AUTOSAR XML (schema 00046)
package /ComponentTypes
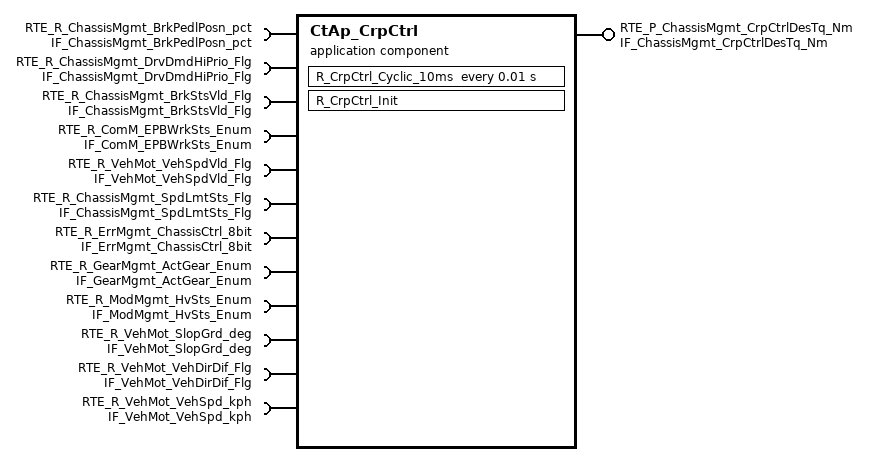
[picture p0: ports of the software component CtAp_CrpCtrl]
  application sw component type CtAp_CrpCtrl
    provide port RTE_P_ChassisMgmt_CrpCtrlDesTq_Nm: nonqueued-sender-com-spec{data-element=tec_ChassisMgmt_CrpCtrlDesTq_Nm, init-value=0}, provided-interface=IF_ChassisMgmt_CrpCtrlDesTq_Nm
    12 x require port:
      RTE_R_ChassisMgmt_BrkPedlPosn_pct: nonqueued-receiver-com-spec{data-element=tec_ChassisMgmt_BrkPedlPosn_pct, filter=data-filter-type=ALWAYS, init-value=0}, required-interface=IF_ChassisMgmt_BrkPedlPosn_pct
      RTE_R_ChassisMgmt_DrvDmdHiPrio_Flg: nonqueued-receiver-com-spec{data-element=tec_ChassisMgmt_DrvDmdHiPrio_Flg, filter=data-filter-type=ALWAYS, init-value=0}, required-interface=IF_ChassisMgmt_DrvDmdHiPrio_Flg
      RTE_R_ChassisMgmt_BrkStsVld_Flg: nonqueued-receiver-com-spec{data-element=tec_ChassisMgmt_BrkStsVld_Flg, filter=data-filter-type=ALWAYS, init-value=0}, required-interface=IF_ChassisMgmt_BrkStsVld_Flg
      RTE_R_ComM_EPBWrkSts_Enum: nonqueued-receiver-com-spec{data-element=tec_ComM_EPBWrkSts_Enum, filter=data-filter-type=ALWAYS, init-value=0}, required-interface=IF_ComM_EPBWrkSts_Enum
      RTE_R_VehMot_VehSpdVld_Flg: nonqueued-receiver-com-spec{data-element=tec_VehMot_VehSpdVld_Flg, filter=data-filter-type=ALWAYS, init-value=0}, required-interface=IF_VehMot_VehSpdVld_Flg
      RTE_R_ChassisMgmt_SpdLmtSts_Flg: nonqueued-receiver-com-spec{data-element=tec_ChassisMgmt_SpdLmtSts_Flg, filter=data-filter-type=ALWAYS, init-value=0}, required-interface=IF_ChassisMgmt_SpdLmtSts_Flg
      RTE_R_ErrMgmt_ChassisCtrl_8bit: nonqueued-receiver-com-spec{data-element=tec_ErrMgmt_ChassisCtrl_8bit, filter=data-filter-type=ALWAYS, init-value=0}, required-interface=IF_ErrMgmt_ChassisCtrl_8bit
      RTE_R_GearMgmt_ActGear_Enum: nonqueued-receiver-com-spec{data-element=tec_GearMgmt_ActGear_Enum, filter=data-filter-type=ALWAYS, init-value=0}, required-interface=IF_GearMgmt_ActGear_Enum
      RTE_R_ModMgmt_HvSts_Enum: nonqueued-receiver-com-spec{data-element=tec_ModMgmt_HvSts_Enum, filter=data-filter-type=ALWAYS, init-value=0}, required-interface=IF_ModMgmt_HvSts_Enum
      RTE_R_VehMot_SlopGrd_deg: nonqueued-receiver-com-spec{data-element=tec_VehMot_SlopGrd_deg, filter=data-filter-type=ALWAYS, init-value=0}, required-interface=IF_VehMot_SlopGrd_deg
      RTE_R_VehMot_VehDirDif_Flg: nonqueued-receiver-com-spec{data-element=tec_VehMot_VehDirDif_Flg, filter=data-filter-type=ALWAYS, init-value=0}, required-interface=IF_VehMot_VehDirDif_Flg
      RTE_R_VehMot_VehSpd_kph: nonqueued-receiver-com-spec{data-element=tec_VehMot_VehSpd_kph, filter=data-filter-type=ALWAYS, init-value=0}, required-interface=IF_VehMot_VehSpd_kph
    behavior CtAp_CrpCtrl_InternalBehavior
      init event CtAp_CrpCtrl_InitEvent: start-on-event=R_CrpCtrl_Init
      timing event TMT_R_CrpCtrl_Cyclic_10ms: start-on-event=R_CrpCtrl_Cyclic_10ms, period=0.01
      runnable R_CrpCtrl_Init
      runnable R_CrpCtrl_Cyclic_10ms
        data-receive-point-by-arguments:
          12 x access:
            REC_RTE_R_ChassisMgmt_BrkPedlPosn_pct_tec_ChassisMgmt_BrkPedlPosn_pct: accessed-variable=RTE_R_ChassisMgmt_BrkPedlPosn_pct.tec_ChassisMgmt_BrkPedlPosn_pct
            REC_RTE_R_ChassisMgmt_BrkStsVld_Flg_tec_ChassisMgmt_BrkStsVld_Flg: accessed-variable=RTE_R_ChassisMgmt_BrkStsVld_Flg.tec_ChassisMgmt_BrkStsVld_Flg
            REC_RTE_R_ChassisMgmt_DrvDmdHiPrio_Flg_tec_ChassisMgmt_DrvDmdHiPrio_Flg: accessed-variable=RTE_R_ChassisMgmt_DrvDmdHiPrio_Flg.tec_ChassisMgmt_DrvDmdHiPrio_Flg
            REC_RTE_R_ChassisMgmt_SpdLmtSts_Flg_tec_ChassisMgmt_SpdLmtSts_Flg: accessed-variable=RTE_R_ChassisMgmt_SpdLmtSts_Flg.tec_ChassisMgmt_SpdLmtSts_Flg
            REC_RTE_R_ComM_EPBWrkSts_Enum_tec_ComM_EPBWrkSts_Enum: accessed-variable=RTE_R_ComM_EPBWrkSts_Enum.tec_ComM_EPBWrkSts_Enum
            REC_RTE_R_ErrMgmt_ChassisCtrl_8bit_tec_ErrMgmt_ChassisCtrl_8bit: accessed-variable=RTE_R_ErrMgmt_ChassisCtrl_8bit.tec_ErrMgmt_ChassisCtrl_8bit
            REC_RTE_R_GearMgmt_ActGear_Enum_tec_GearMgmt_ActGear_Enum: accessed-variable=RTE_R_GearMgmt_ActGear_Enum.tec_GearMgmt_ActGear_Enum
            REC_RTE_R_ModMgmt_HvSts_Enum_tec_ModMgmt_HvSts_Enum: accessed-variable=RTE_R_ModMgmt_HvSts_Enum.tec_ModMgmt_HvSts_Enum
            REC_RTE_R_VehMot_SlopGrd_deg_tec_VehMot_SlopGrd_deg: accessed-variable=RTE_R_VehMot_SlopGrd_deg.tec_VehMot_SlopGrd_deg
            REC_RTE_R_VehMot_VehDirDif_Flg_tec_VehMot_VehDirDif_Flg: accessed-variable=RTE_R_VehMot_VehDirDif_Flg.tec_VehMot_VehDirDif_Flg
            REC_RTE_R_VehMot_VehSpdVld_Flg_tec_VehMot_VehSpdVld_Flg: accessed-variable=RTE_R_VehMot_VehSpdVld_Flg.tec_VehMot_VehSpdVld_Flg
            REC_RTE_R_VehMot_VehSpd_kph_tec_VehMot_VehSpd_kph: accessed-variable=RTE_R_VehMot_VehSpd_kph.tec_VehMot_VehSpd_kph
        data-send-points:
          access SEND_RTE_P_ChassisMgmt_CrpCtrlDesTq_Nm_tec_ChassisMgmt_CrpCtrlDesTq_Nm: accessed-variable=RTE_P_ChassisMgmt_CrpCtrlDesTq_Nm.tec_ChassisMgmt_CrpCtrlDesTq_Nm
  swc implementation CtAp_CrpCtrl_Implementation: behavior=CtAp_CrpCtrl_InternalBehavior
    code-descriptors:
      code Default: artifact-descriptors=autosar-engineering-object=category=SWOBJ
